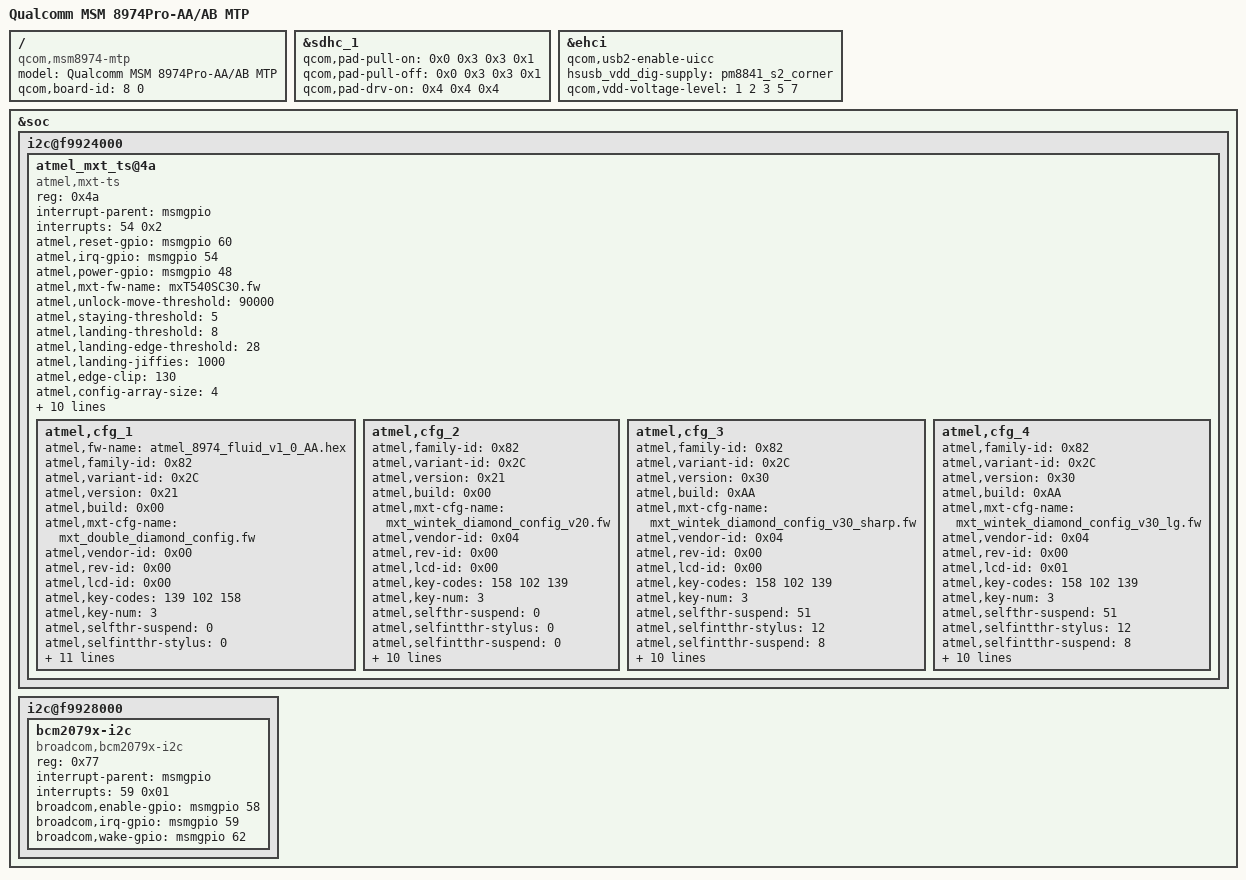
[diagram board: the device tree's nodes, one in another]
/* Copyright (c) 2013-2014, The Linux Foundation. All rights reserved.
 * Copyright (C) 2015 XiaoMi, Inc.
 *
 * This program is free software; you can redistribute it and/or modify
 * it under the terms of the GNU General Public License version 2 and
 * only version 2 as published by the Free Software Foundation.
 *
 * This program is distributed in the hope that it will be useful,
 * but WITHOUT ANY WARRANTY; without even the implied warranty of
 * MERCHANTABILITY or FITNESS FOR A PARTICULAR PURPOSE.  See the
 * GNU General Public License for more details.
 */

/dts-v1/;

/include/ "msm8974pro-ab-pm8941.dtsi"
/include/ "msm8974-mtp.dtsi"

/ {
	model = "Qualcomm MSM 8974Pro-AA/AB MTP";
	compatible = "qcom,msm8974-mtp", "qcom,msm8974", "qcom,mtp";
	qcom,board-id = <8 0>;
};


&sdhc_1 {
	qcom,pad-pull-on = <0x0 0x3 0x3 0x1>; /* no-pull, pull-up, pull-up, pull-down */
	qcom,pad-pull-off = <0x0 0x3 0x3 0x1>; /* no-pull, pull-up, pull-up, pull-down */
	qcom,pad-drv-on = <0x4 0x4 0x4>; /* 10mA, 10mA, 10mA */
};

&ehci {
	status = "ok";
	qcom,usb2-enable-uicc;
	hsusb_vdd_dig-supply = <&pm8841_s2_corner>;
	qcom,vdd-voltage-level = <1 2 3 5 7>;
};

&soc {

	i2c@f9924000 {
		atmel_mxt_ts@4a {
			compatible = "atmel,mxt-ts";
			reg = <0x4a>;
			interrupt-parent = <&msmgpio>;
			interrupts = <54 0x2>;
			atmel,reset-gpio = <&msmgpio 60 0x00>;
			atmel,irq-gpio = <&msmgpio 54 0x2008>;
			atmel,power-gpio = <&msmgpio 48 0x00>;
			atmel,mxt-fw-name = "mxT540SC30.fw";
			atmel,unlock-move-threshold = <90000>;
			atmel,staying-threshold = <5>;
			atmel,landing-threshold = <8>;
			atmel,landing-edge-threshold = <28>;
			atmel,landing-jiffies = <1000>;
			atmel,edge-clip = <130>;
			atmel,config-array-size = <4>;
			atmel,irqflags = <0x2008>;
			atmel,gpio-mask = <0x4>;
			atmel,linearity-reg-pos = <11 12 17 18>;
			atmel,linearity-singlex = <10 10 178 50>;
			atmel,linearity-dualx = <24 244 63 51>;
			atmel,linearity-para-num = <4>;
			atmel,rx-num = <18>;
			atmel,tx-num = <30>;
			atmel,ref-diff-threshold = <400>;
			atmel,ref-diff-halfline-threshold = <500>;
			atmel,cfg_1 {
				atmel,fw-name = "atmel_8974_fluid_v1_0_AA.hex";
				atmel,family-id = <0x82>;
				atmel,variant-id = <0x2C>;
				atmel,version = <0x21>;
				atmel,build = <0x00>;
				atmel,mxt-cfg-name = "mxt_double_diamond_config.fw";
				atmel,vendor-id = <0x00>;
				atmel,rev-id = <0x00>;
				atmel,lcd-id = <0x00>;
				atmel,key-codes = <139 102 158>;
				atmel,key-num = <3>;
				atmel,selfthr-suspend = <0>;
				atmel,selfintthr-stylus = <0>;
				atmel,selfintthr-suspend = <0>;
				atmel,t71-tchthr-pos = <22>;
				atmel,self-no-touch-threshold = <0>;
				atmel,mult-no-touch-threshold = <0>;
				atmel,self-chgtime-min = <0>;
				atmel,self-chgtime-max = <0>;
				atmel,mult-intthr-sensitive = <12>;
				atmel,mult-intthr-not-sensitive = <20>;
				atmel,atchthr-sensitive = <6>;
				atmel,mult-tchthr-sensitive = <0>;
				atmel,mult-tchthr-not-sensitive = <0>;
			};
			atmel,cfg_2 {
				atmel,family-id = <0x82>;
				atmel,variant-id = <0x2C>;
				atmel,version = <0x21>;
				atmel,build = <0x00>;
				atmel,mxt-cfg-name = "mxt_wintek_diamond_config_v20.fw";
				atmel,vendor-id = <0x04>;
				atmel,rev-id = <0x00>;
				atmel,lcd-id = <0x00>;
				atmel,key-codes = <158 102 139>;
				atmel,key-num = <3>;
				atmel,selfthr-suspend = <0>;
				atmel,selfintthr-stylus = <0>;
				atmel,selfintthr-suspend = <0>;
				atmel,t71-tchthr-pos = <22>;
				atmel,self-no-touch-threshold = <0>;
				atmel,mult-no-touch-threshold = <0>;
				atmel,self-chgtime-min = <0>;
				atmel,self-chgtime-max = <0>;
				atmel,mult-intthr-sensitive = <12>;
				atmel,mult-intthr-not-sensitive = <20>;
				atmel,atchthr-sensitive = <6>;
				atmel,mult-tchthr-sensitive = <0>;
				atmel,mult-tchthr-not-sensitive = <0>;
			};
			atmel,cfg_3 {
				atmel,family-id = <0x82>;
				atmel,variant-id = <0x2C>;
				atmel,version = <0x30>;
				atmel,build = <0xAA>;
				atmel,mxt-cfg-name = "mxt_wintek_diamond_config_v30_sharp.fw";
				atmel,vendor-id = <0x04>;
				atmel,rev-id = <0x00>;
				atmel,lcd-id = <0x00>;
				atmel,key-codes = <158 102 139>;
				atmel,key-num = <3>;
				atmel,selfthr-suspend = <51>;
				atmel,selfintthr-stylus = <12>;
				atmel,selfintthr-suspend = <8>;
				atmel,t71-tchthr-pos = <22>;
				atmel,self-no-touch-threshold = <220>;
				atmel,mult-no-touch-threshold = <70>;
				atmel,self-chgtime-min = <70>;
				atmel,self-chgtime-max = <100>;
				atmel,mult-intthr-sensitive = <12>;
				atmel,mult-intthr-not-sensitive = <20>;
				atmel,atchthr-sensitive = <6>;
				atmel,mult-tchthr-sensitive = <0x3C>;
				atmel,mult-tchthr-not-sensitive = <0x20>;
			};
			atmel,cfg_4 {
				atmel,family-id = <0x82>;
				atmel,variant-id = <0x2C>;
				atmel,version = <0x30>;
				atmel,build = <0xAA>;
				atmel,mxt-cfg-name = "mxt_wintek_diamond_config_v30_lg.fw";
				atmel,vendor-id = <0x04>;
				atmel,rev-id = <0x00>;
				atmel,lcd-id = <0x01>;
				atmel,key-codes = <158 102 139>;
				atmel,key-num = <3>;
				atmel,selfthr-suspend = <51>;
				atmel,selfintthr-stylus = <12>;
				atmel,selfintthr-suspend = <8>;
				atmel,t71-tchthr-pos = <22>;
				atmel,self-no-touch-threshold = <220>;
				atmel,mult-no-touch-threshold = <70>;
				atmel,self-chgtime-min = <70>;
				atmel,self-chgtime-max = <100>;
				atmel,mult-intthr-sensitive = <12>;
				atmel,mult-intthr-not-sensitive = <20>;
				atmel,atchthr-sensitive = <6>;
				atmel,mult-tchthr-sensitive = <0x3C>;
				atmel,mult-tchthr-not-sensitive = <0x20>;
			};
		};
	};

	i2c@f9928000 {
		bcm2079x-i2c {
			compatible = "broadcom,bcm2079x-i2c";
			reg = <0x77>;
			interrupt-parent = <&msmgpio>;
			interrupts = <59 0x01>;
			broadcom,enable-gpio = <&msmgpio 58 0x00>;
			broadcom,irq-gpio = <&msmgpio 59 0x00>;
			broadcom,wake-gpio = <&msmgpio 62 0x00>;
		};
	};
};
